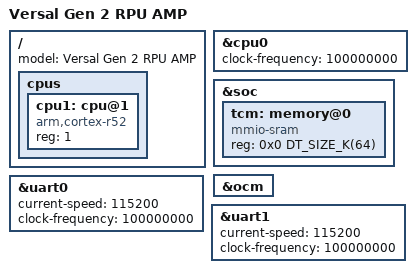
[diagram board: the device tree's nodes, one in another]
/*
 * Copyright (c) 2025, Advanced Micro Devices, Inc.
 *
 * SPDX-License-Identifier: Apache-2.0
 *
 * Base DTS for Versal Gen 2 RPU AMP (split-mode).
 * Adds cpu@1 and enables both UARTs for dual-core operation.
 * Sub-variants core0/core1 select their own memory and console.
 */

/dts-v1/;
#include <arm/xilinx/versal2_r52.dtsi>

/ {
	model = "Versal Gen 2 RPU AMP";

	cpus {
		cpu1: cpu@1 {
			device_type = "cpu";
			compatible = "arm,cortex-r52";
			reg = <1>;
		};
	};
};

&cpu0 {
	clock-frequency = <100000000>;
};

&soc {
	tcm: memory@0 {
		compatible = "mmio-sram";
		reg = <0x0 DT_SIZE_K(64)>;
	};
};

&ocm {
	status = "okay";
};

&uart0 {
	status = "okay";
	current-speed = <115200>;
	clock-frequency = <100000000>;
};

&uart1 {
	status = "okay";
	current-speed = <115200>;
	clock-frequency = <100000000>;
};
